# ATSAME54P20A device description
Architecture: CORTEX-M4; Family: SAMD; Series: SAME54
Registers are 32-bit, read-write, reset 0x0 unless marked. A register's access mark holds for its fields unless they carry their own. Offsets are from the block's base; [hi:lo] are bit positions; {n}, {i} and the like mark numbered series.

## ICM_DESCRIPTOR — Integrity Check Monitor
0x00 RADDR reset not defined — Region Start Address
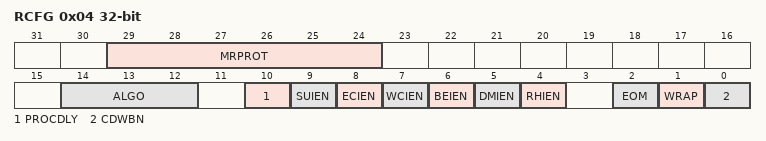
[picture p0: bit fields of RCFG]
0x04 RCFG — Region Configuration
  [29:24] MRPROT — Memory Region AHB Protection
  [14:12] ALGO — SHA Algorithm
  [10] PROCDLY — SHA Processing Delay
    0=SHORT; 1=LONG
  [9] SUIEN — Region Status Updated Interrupt Enable
    0=EN; 1=DIS
  [8] ECIEN — Region End bit Condition detected Interrupt Enable
    0=EN; 1=DIS
  [7] WCIEN — Region Wrap Condition Detected Interrupt Enable
    0=EN; 1=DIS
  [6] BEIEN — Region Bus Error Interrupt Enable
    0=EN; 1=DIS
  [5] DMIEN — Region Digest Mismatch Interrupt Enable
    0=EN; 1=DIS
  [4] RHIEN — Region Hash Interrupt Enable
    0=EN; 1=DIS
  [2] EOM — End of Monitoring
    0=NO; 1=YES
  [1] WRAP — Region Wrap
    0=NO; 1=YES
  [0] CDWBN — Compare Digest Write Back
    0=WRBA; 1=COMP
0x08 RCTRL reset not defined — Region Control
  [15:0] TRSIZE — Transfer Size
0x0C RNEXT reset not defined — Region Next Address

## MCLK — Main Clock
Instances: MCLK 0x40000800
0x01 INTENCLR 8-bit (atomic clear) — Interrupt Enable Clear
  [0] CKRDY — Clock Ready Interrupt Enable
0x02 INTENSET 8-bit (atomic set) — Interrupt Enable Set
  [0] CKRDY — Clock Ready Interrupt Enable
0x03 INTFLAG 8-bit reset 0x1 (atomic clear) — Interrupt Flag Status and Clear
  [0] CKRDY — Clock Ready
0x04 HSDIV 8-bit ro reset 0x1 — HS Clock Division
  [7:0] DIV — CPU Clock Division Factor
    1=Divide by 1
0x05 CPUDIV 8-bit reset 0x1 — CPU Clock Division
  [7:0] DIV — Low-Power Clock Division Factor
    1=Divide by 1; 2=Divide by 2; 4=Divide by 4; 8=Divide by 8; 16=Divide by 16; 32=Divide by 32; 64=Divide by 64; 128=Divide by 128
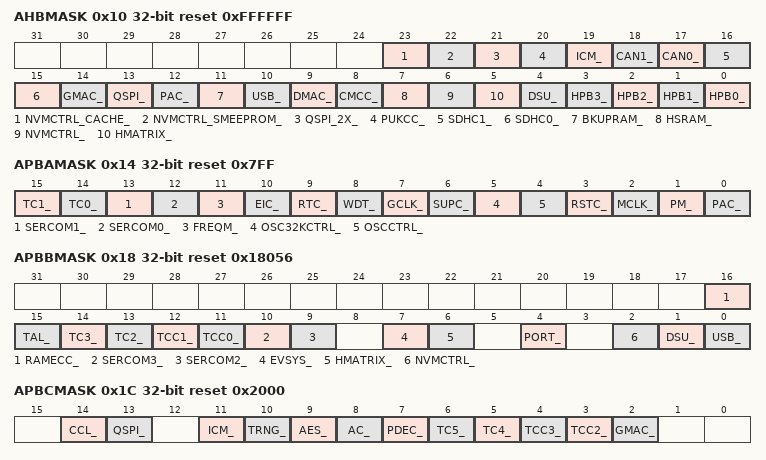
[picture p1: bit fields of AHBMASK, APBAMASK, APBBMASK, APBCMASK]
0x10 AHBMASK reset 0xFFFFFF
  [23] NVMCTRL_CACHE_ — NVMCTRL_CACHE AHB Clock Mask
  [22] NVMCTRL_SMEEPROM_ — NVMCTRL_SMEEPROM AHB Clock Mask
  [21] QSPI_2X_ — QSPI_2X AHB Clock Mask
  [20] PUKCC_ — PUKCC AHB Clock Mask
  [19] ICM_ — ICM AHB Clock Mask
  [18] CAN1_ — CAN1 AHB Clock Mask
  [17] CAN0_ — CAN0 AHB Clock Mask
  [16] SDHC1_ — SDHC1 AHB Clock Mask
  [15] SDHC0_ — SDHC0 AHB Clock Mask
  [14] GMAC_ — GMAC AHB Clock Mask
  [13] QSPI_ — QSPI AHB Clock Mask
  [12] PAC_ — PAC AHB Clock Mask
  [11] BKUPRAM_ — BKUPRAM AHB Clock Mask
  [10] USB_ — USB AHB Clock Mask
  [9] DMAC_ — DMAC AHB Clock Mask
  [8] CMCC_ — CMCC AHB Clock Mask
  [7] HSRAM_ — HSRAM AHB Clock Mask
  [6] NVMCTRL_ — NVMCTRL AHB Clock Mask
  [5] HMATRIX_ — HMATRIX AHB Clock Mask
  [4] DSU_ — DSU AHB Clock Mask
  [n] HPB{n}_ (n=0..3) — HPB{n} AHB Clock Mask
0x14 APBAMASK reset 0x7FF
  [15] TC1_ — TC1 APB Clock Enable
  [14] TC0_ — TC0 APB Clock Enable
  [13] SERCOM1_ — SERCOM1 APB Clock Enable
  [12] SERCOM0_ — SERCOM0 APB Clock Enable
  [11] FREQM_ — FREQM APB Clock Enable
  [10] EIC_ — EIC APB Clock Enable
  [9] RTC_ — RTC APB Clock Enable
  [8] WDT_ — WDT APB Clock Enable
  [7] GCLK_ — GCLK APB Clock Enable
  [6] SUPC_ — SUPC APB Clock Enable
  [5] OSC32KCTRL_ — OSC32KCTRL APB Clock Enable
  [4] OSCCTRL_ — OSCCTRL APB Clock Enable
  [3] RSTC_ — RSTC APB Clock Enable
  [2] MCLK_ — MCLK APB Clock Enable
  [1] PM_ — PM APB Clock Enable
  [0] PAC_ — PAC APB Clock Enable
0x18 APBBMASK reset 0x18056
  [16] RAMECC_ — RAMECC APB Clock Enable
  [15] TAL_ — TAL APB Clock Enable
  [14] TC3_ — TC3 APB Clock Enable
  [13] TC2_ — TC2 APB Clock Enable
  [12] TCC1_ — TCC1 APB Clock Enable
  [11] TCC0_ — TCC0 APB Clock Enable
  [10] SERCOM3_ — SERCOM3 APB Clock Enable
  [9] SERCOM2_ — SERCOM2 APB Clock Enable
  [7] EVSYS_ — EVSYS APB Clock Enable
  [6] HMATRIX_ — HMATRIX APB Clock Enable
  [4] PORT_ — PORT APB Clock Enable
  [2] NVMCTRL_ — NVMCTRL APB Clock Enable
  [1] DSU_ — DSU APB Clock Enable
  [0] USB_ — USB APB Clock Enable
0x1C APBCMASK reset 0x2000
  [14] CCL_ — CCL APB Clock Enable
  [13] QSPI_ — QSPI APB Clock Enable
  [11] ICM_ — ICM APB Clock Enable
  [10] TRNG_ — TRNG APB Clock Enable
  [9] AES_ — AES APB Clock Enable
  [8] AC_ — AC APB Clock Enable
  [7] PDEC_ — PDEC APB Clock Enable
  [6] TC5_ — TC5 APB Clock Enable
  [5] TC4_ — TC4 APB Clock Enable
  [4] TCC3_ — TCC3 APB Clock Enable
  [3] TCC2_ — TCC2 APB Clock Enable
  [2] GMAC_ — GMAC APB Clock Enable
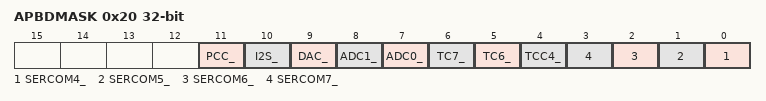
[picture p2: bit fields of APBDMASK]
0x20 APBDMASK
  [11] PCC_ — PCC APB Clock Enable
  [10] I2S_ — I2S APB Clock Enable
  [9] DAC_ — DAC APB Clock Enable
  [8] ADC1_ — ADC1 APB Clock Enable
  [7] ADC0_ — ADC0 APB Clock Enable
  [6] TC7_ — TC7 APB Clock Enable
  [5] TC6_ — TC6 APB Clock Enable
  [4] TCC4_ — TCC4 APB Clock Enable
  [n-4] SERCOM{n}_ (n=4..7) — SERCOM{n} APB Clock Enable
